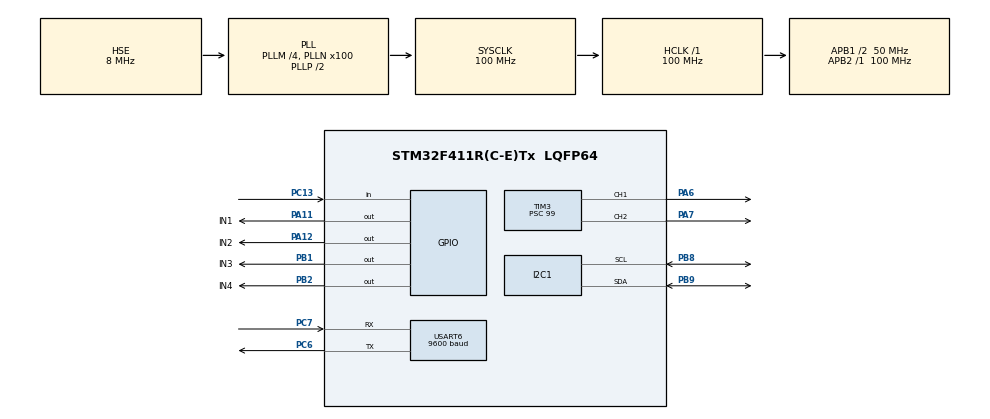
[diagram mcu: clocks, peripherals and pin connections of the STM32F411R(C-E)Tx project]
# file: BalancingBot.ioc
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Dma.Request0=USART6_RX
Dma.USART6_RX.0.Direction=DMA_PERIPH_TO_MEMORY
Dma.USART6_RX.0.FIFOMode=DMA_FIFOMODE_DISABLE
Dma.USART6_RX.0.Instance=DMA2_Stream1
Dma.USART6_RX.0.MemDataAlignment=DMA_MDATAALIGN_BYTE
Dma.USART6_RX.0.MemInc=DMA_MINC_ENABLE
Dma.USART6_RX.0.Mode=DMA_NORMAL
Dma.USART6_RX.0.PeriphDataAlignment=DMA_PDATAALIGN_BYTE
Dma.USART6_RX.0.PeriphInc=DMA_PINC_DISABLE
Dma.USART6_RX.0.Priority=DMA_PRIORITY_LOW
I2C1.NoStretchMode=I2C_NOSTRETCH_ENABLE
Mcu.Family=STM32F4
Mcu.Name=STM32F411R(C-E)Tx
Mcu.Package=LQFP64
NVIC.DMA2_Stream1_IRQn=true\:0\:0\:false\:false\:true\:false\:true\:true
NVIC.PriorityGroup=NVIC_PRIORITYGROUP_4
NVIC.USART6_IRQn=true\:0\:0\:false\:false\:true\:true\:true\:true
PA11.GPIO_Label=IN1
PA11.Signal=GPIO_Output
PA12.GPIO_Label=IN2
PA12.Signal=GPIO_Output
PA13.Mode=Serial_Wire
PA13.Signal=SYS_JTMS-SWDIO
PA14.Mode=Serial_Wire
PA14.Signal=SYS_JTCK-SWCLK
PA6.Signal=S_TIM3_CH1
PA7.Signal=S_TIM3_CH2
PB1.GPIO_Label=IN3
PB1.Signal=GPIO_Output
PB2.GPIO_Label=IN4
PB2.Signal=GPIO_Output
PB8.Mode=I2C
PB8.Signal=I2C1_SCL
PB9.Mode=I2C
PB9.Signal=I2C1_SDA
PC13-ANTI_TAMP.Signal=GPIO_Input
PC14-OSC32_IN.Mode=LSE-External-Oscillator
PC14-OSC32_IN.Signal=RCC_OSC32_IN
PC15-OSC32_OUT.Mode=LSE-External-Oscillator
PC15-OSC32_OUT.Signal=RCC_OSC32_OUT
PC6.Mode=Asynchronous
PC6.Signal=USART6_TX
PC7.Mode=Asynchronous
PC7.Signal=USART6_RX
PH0\ -\ OSC_IN.Mode=HSE-External-Oscillator
PH0\ -\ OSC_IN.Signal=RCC_OSC_IN
PH1\ -\ OSC_OUT.Mode=HSE-External-Oscillator
PH1\ -\ OSC_OUT.Signal=RCC_OSC_OUT
ProjectManager.HeapSize=0x200
ProjectManager.StackSize=0x400
ProjectManager.TargetToolchain=STM32CubeIDE
RCC.48MHZClocksFreq_Value=50000000
RCC.AHBFreq_Value=100000000
RCC.APB1CLKDivider=RCC_HCLK_DIV2
RCC.APB1Freq_Value=50000000
RCC.APB1TimFreq_Value=100000000
RCC.APB2Freq_Value=100000000
RCC.APB2TimFreq_Value=100000000
RCC.CortexFreq_Value=100000000
RCC.HCLKFreq_Value=100000000
RCC.HSE_VALUE=8000000
RCC.HSI_VALUE=16000000
RCC.PLLM=4
RCC.PLLN=100
RCC.PLLSourceVirtual=RCC_PLLSOURCE_HSE
RCC.SYSCLKFreq_VALUE=100000000
RCC.SYSCLKSource=RCC_SYSCLKSOURCE_PLLCLK
RCC.VCOOutputFreq_Value=200000000
SH.S_TIM3_CH1.0=TIM3_CH1,PWM Generation1 CH1
SH.S_TIM3_CH2.0=TIM3_CH2,PWM Generation2 CH2
TIM3.AutoReloadPreload=TIM_AUTORELOAD_PRELOAD_ENABLE
TIM3.Channel-PWM\ Generation1\ CH1=TIM_CHANNEL_1
TIM3.Channel-PWM\ Generation2\ CH2=TIM_CHANNEL_2
TIM3.Period=999
TIM3.Prescaler=99
USART6.BaudRate=9600
USART6.VirtualMode=VM_ASYNC
board=custom

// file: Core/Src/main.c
/* USER CODE BEGIN Header */
/**
  ******************************************************************************
  * @file           : main.c
  * @brief          : Main program body
  ******************************************************************************
  * @attention
  *
  * Copyright (c) 2026 STMicroelectronics.
  * All rights reserved.
  *
  * This software is licensed under terms that can be found in the LICENSE file
  * in the root directory of this software component.
  * If no LICENSE file comes with this software, it is provided AS-IS.
  *
  ******************************************************************************
  */
/* USER CODE END Header */
#include "main.h"

/* USER CODE BEGIN Includes */
#include "../App/ap_main.h"
/* USER CODE END Includes */

I2C_HandleTypeDef hi2c1;

TIM_HandleTypeDef htim3;

UART_HandleTypeDef huart6;
DMA_HandleTypeDef hdma_usart6_rx;

void SystemClock_Config(void);
static void MX_GPIO_Init(void);
static void MX_DMA_Init(void);
static void MX_I2C1_Init(void);
static void MX_TIM3_Init(void);
static void MX_USART6_UART_Init(void);

int main(void)
{

  /* MCU Configuration--------------------------------------------------------*/

  /* Reset of all peripherals, Initializes the Flash interface and the Systick. */
  HAL_Init();

  /* Configure the system clock */
  SystemClock_Config();

  /* Initialize all configured peripherals */
  MX_GPIO_Init();
  MX_DMA_Init();
  MX_I2C1_Init();
  MX_TIM3_Init();
  MX_USART6_UART_Init();
  /* USER CODE BEGIN 2 */
  ap_init();
  /* USER CODE END 2 */

  /* Infinite loop */
  while (1)
  {

    /* USER CODE BEGIN 3 */
    ap_exe();
  }
  /* USER CODE END 3 */
}

void SystemClock_Config(void)
{
  RCC_OscInitTypeDef RCC_OscInitStruct = {0};
  RCC_ClkInitTypeDef RCC_ClkInitStruct = {0};

  /** Configure the main internal regulator output voltage
  */
  __HAL_RCC_PWR_CLK_ENABLE();
  __HAL_PWR_VOLTAGESCALING_CONFIG(PWR_REGULATOR_VOLTAGE_SCALE1);

  /** Initializes the RCC Oscillators according to the specified parameters
  * in the RCC_OscInitTypeDef structure.
  */
  RCC_OscInitStruct.OscillatorType = RCC_OSCILLATORTYPE_HSE;
  RCC_OscInitStruct.HSEState = RCC_HSE_ON;
  RCC_OscInitStruct.PLL.PLLState = RCC_PLL_ON;
  RCC_OscInitStruct.PLL.PLLSource = RCC_PLLSOURCE_HSE;
  RCC_OscInitStruct.PLL.PLLM = 4;
  RCC_OscInitStruct.PLL.PLLN = 100;
  RCC_OscInitStruct.PLL.PLLP = RCC_PLLP_DIV2;
  RCC_OscInitStruct.PLL.PLLQ = 4;
  if (HAL_RCC_OscConfig(&RCC_OscInitStruct) != HAL_OK)
  {
    Error_Handler();
  }

  /** Initializes the CPU, AHB and APB buses clocks
  */
  RCC_ClkInitStruct.ClockType = RCC_CLOCKTYPE_HCLK|RCC_CLOCKTYPE_SYSCLK
                              |RCC_CLOCKTYPE_PCLK1|RCC_CLOCKTYPE_PCLK2;
  RCC_ClkInitStruct.SYSCLKSource = RCC_SYSCLKSOURCE_PLLCLK;
  RCC_ClkInitStruct.AHBCLKDivider = RCC_SYSCLK_DIV1;
  RCC_ClkInitStruct.APB1CLKDivider = RCC_HCLK_DIV2;
  RCC_ClkInitStruct.APB2CLKDivider = RCC_HCLK_DIV1;

  if (HAL_RCC_ClockConfig(&RCC_ClkInitStruct, FLASH_LATENCY_3) != HAL_OK)
  {
    Error_Handler();
  }
}

static void MX_I2C1_Init(void)
{

  hi2c1.Instance = I2C1;
  hi2c1.Init.ClockSpeed = 100000;
  hi2c1.Init.DutyCycle = I2C_DUTYCYCLE_2;
  hi2c1.Init.OwnAddress1 = 0;
  hi2c1.Init.AddressingMode = I2C_ADDRESSINGMODE_7BIT;
  hi2c1.Init.DualAddressMode = I2C_DUALADDRESS_DISABLE;
  hi2c1.Init.OwnAddress2 = 0;
  hi2c1.Init.GeneralCallMode = I2C_GENERALCALL_DISABLE;
  hi2c1.Init.NoStretchMode = I2C_NOSTRETCH_ENABLE;
  if (HAL_I2C_Init(&hi2c1) != HAL_OK)
  {
    Error_Handler();
  }

}

static void MX_TIM3_Init(void)
{

  TIM_MasterConfigTypeDef sMasterConfig = {0};
  TIM_OC_InitTypeDef sConfigOC = {0};

  htim3.Instance = TIM3;
  htim3.Init.Prescaler = 99;
  htim3.Init.CounterMode = TIM_COUNTERMODE_UP;
  htim3.Init.Period = 999;
  htim3.Init.ClockDivision = TIM_CLOCKDIVISION_DIV1;
  htim3.Init.AutoReloadPreload = TIM_AUTORELOAD_PRELOAD_ENABLE;
  if (HAL_TIM_PWM_Init(&htim3) != HAL_OK)
  {
    Error_Handler();
  }
  sMasterConfig.MasterOutputTrigger = TIM_TRGO_RESET;
  sMasterConfig.MasterSlaveMode = TIM_MASTERSLAVEMODE_DISABLE;
  if (HAL_TIMEx_MasterConfigSynchronization(&htim3, &sMasterConfig) != HAL_OK)
  {
    Error_Handler();
  }
  sConfigOC.OCMode = TIM_OCMODE_PWM1;
  sConfigOC.Pulse = 0;
  sConfigOC.OCPolarity = TIM_OCPOLARITY_HIGH;
  sConfigOC.OCFastMode = TIM_OCFAST_DISABLE;
  if (HAL_TIM_PWM_ConfigChannel(&htim3, &sConfigOC, TIM_CHANNEL_1) != HAL_OK)
  {
    Error_Handler();
  }
  if (HAL_TIM_PWM_ConfigChannel(&htim3, &sConfigOC, TIM_CHANNEL_2) != HAL_OK)
  {
    Error_Handler();
  }
  HAL_TIM_MspPostInit(&htim3);

}

static void MX_USART6_UART_Init(void)
{

  huart6.Instance = USART6;
  huart6.Init.BaudRate = 9600;
  huart6.Init.WordLength = UART_WORDLENGTH_8B;
  huart6.Init.StopBits = UART_STOPBITS_1;
  huart6.Init.Parity = UART_PARITY_NONE;
  huart6.Init.Mode = UART_MODE_TX_RX;
  huart6.Init.HwFlowCtl = UART_HWCONTROL_NONE;
  huart6.Init.OverSampling = UART_OVERSAMPLING_16;
  if (HAL_UART_Init(&huart6) != HAL_OK)
  {
    Error_Handler();
  }

}

static void MX_DMA_Init(void)
{

  /* DMA controller clock enable */
  __HAL_RCC_DMA2_CLK_ENABLE();

  /* DMA interrupt init */
  /* DMA2_Stream1_IRQn interrupt configuration */
  HAL_NVIC_SetPriority(DMA2_Stream1_IRQn, 0, 0);
  HAL_NVIC_EnableIRQ(DMA2_Stream1_IRQn);

}

static void MX_GPIO_Init(void)
{
  GPIO_InitTypeDef GPIO_InitStruct = {0};

  /* GPIO Ports Clock Enable */
  __HAL_RCC_GPIOC_CLK_ENABLE();
  __HAL_RCC_GPIOH_CLK_ENABLE();
  __HAL_RCC_GPIOA_CLK_ENABLE();
  __HAL_RCC_GPIOB_CLK_ENABLE();

  /*Configure GPIO pin Output Level */
  HAL_GPIO_WritePin(GPIOB, IN3_Pin|IN4_Pin, GPIO_PIN_RESET);

  /*Configure GPIO pin Output Level */
  HAL_GPIO_WritePin(GPIOA, IN1_Pin|IN2_Pin, GPIO_PIN_RESET);

  /*Configure GPIO pin : PC13 */
  GPIO_InitStruct.Pin = GPIO_PIN_13;
  GPIO_InitStruct.Mode = GPIO_MODE_INPUT;
  GPIO_InitStruct.Pull = GPIO_NOPULL;
  HAL_GPIO_Init(GPIOC, &GPIO_InitStruct);

  /*Configure GPIO pins : IN3_Pin IN4_Pin */
  GPIO_InitStruct.Pin = IN3_Pin|IN4_Pin;
  GPIO_InitStruct.Mode = GPIO_MODE_OUTPUT_PP;
  GPIO_InitStruct.Pull = GPIO_NOPULL;
  GPIO_InitStruct.Speed = GPIO_SPEED_FREQ_LOW;
  HAL_GPIO_Init(GPIOB, &GPIO_InitStruct);

  /*Configure GPIO pins : IN1_Pin IN2_Pin */
  GPIO_InitStruct.Pin = IN1_Pin|IN2_Pin;
  GPIO_InitStruct.Mode = GPIO_MODE_OUTPUT_PP;
  GPIO_InitStruct.Pull = GPIO_NOPULL;
  GPIO_InitStruct.Speed = GPIO_SPEED_FREQ_LOW;
  HAL_GPIO_Init(GPIOA, &GPIO_InitStruct);

}

void Error_Handler(void)
{
  __disable_irq();
  while (1)
  {
  }
}
